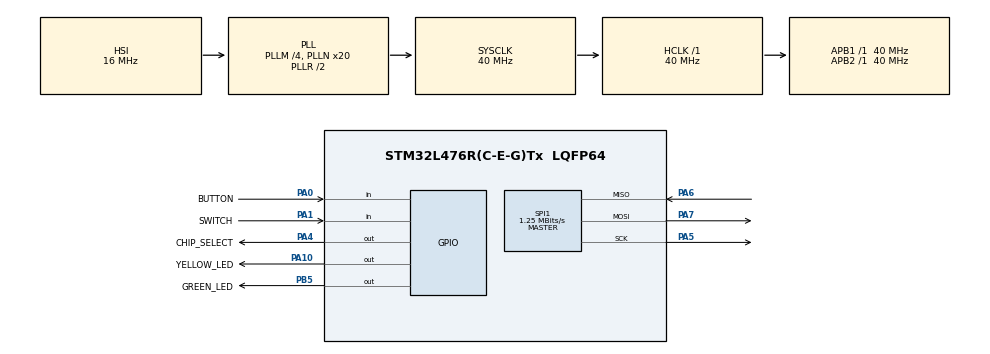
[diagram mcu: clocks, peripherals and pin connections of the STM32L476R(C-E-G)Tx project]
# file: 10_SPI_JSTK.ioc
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Mcu.Family=STM32L4
Mcu.Name=STM32L476R(C-E-G)Tx
Mcu.Package=LQFP64
NVIC.PriorityGroup=NVIC_PRIORITYGROUP_4
PA0.GPIO_Label=BUTTON
PA0.Signal=GPIO_Input
PA1.GPIO_Label=SWITCH
PA1.Signal=GPIO_Input
PA10.GPIO_Label=YELLOW_LED
PA10.Signal=GPIO_Output
PA13\ (JTMS-SWDIO).Mode=Serial_Wire
PA13\ (JTMS-SWDIO).Signal=SYS_JTMS-SWDIO
PA14\ (JTCK-SWCLK).Mode=Serial_Wire
PA14\ (JTCK-SWCLK).Signal=SYS_JTCK-SWCLK
PA4.GPIO_Label=CHIP_SELECT
PA4.Signal=GPIO_Output
PA5.Mode=Full_Duplex_Master
PA5.Signal=SPI1_SCK
PA6.Mode=Full_Duplex_Master
PA6.Signal=SPI1_MISO
PA7.Mode=Full_Duplex_Master
PA7.Signal=SPI1_MOSI
PB5.GPIO_Label=GREEN_LED
PB5.Signal=GPIO_Output
PH0-OSC_IN\ (PH0).Mode=HSE-External-Oscillator
PH0-OSC_IN\ (PH0).Signal=RCC_OSC_IN
PH1-OSC_OUT\ (PH1).Mode=HSE-External-Oscillator
PH1-OSC_OUT\ (PH1).Signal=RCC_OSC_OUT
ProjectManager.HeapSize=0x200
ProjectManager.StackSize=0x400
ProjectManager.TargetToolchain=MDK-ARM V5
RCC.ADCFreq_Value=16000000
RCC.AHBFreq_Value=40000000
RCC.APB1Freq_Value=40000000
RCC.APB1TimFreq_Value=40000000
RCC.APB2Freq_Value=40000000
RCC.APB2TimFreq_Value=40000000
RCC.CortexFreq_Value=40000000
RCC.HCLKFreq_Value=40000000
RCC.HSE_VALUE=8000000
RCC.HSI_VALUE=16000000
RCC.LSE_VALUE=32768
RCC.MSI_VALUE=4000000
RCC.PLLM=4
RCC.PLLN=20
RCC.PLLSourceVirtual=RCC_PLLSOURCE_HSI
RCC.PREFETCH_ENABLE=1
RCC.SYSCLKFreq_VALUE=40000000
RCC.SYSCLKSource=RCC_SYSCLKSOURCE_PLLCLK
RCC.USBFreq_Value=16000000
RCC.VCOOutputFreq_Value=80000000
SPI1.BaudRatePrescaler=SPI_BAUDRATEPRESCALER_32
SPI1.CalculateBaudRate=1.25 MBits/s
SPI1.DataSize=SPI_DATASIZE_8BIT
SPI1.Direction=SPI_DIRECTION_2LINES
SPI1.FirstBit=SPI_FIRSTBIT_MSB
SPI1.Mode=SPI_MODE_MASTER
SPI1.VirtualType=VM_MASTER
board=NUCLEO-L476RG

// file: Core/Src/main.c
/* USER CODE BEGIN Header */
/**
  ******************************************************************************
  * @file           : main.c
  * @brief          : Main program body
  ******************************************************************************
  * @attention
  *
  * Copyright (c) 2023 STMicroelectronics.
  * All rights reserved.
  *
  * This software is licensed under terms that can be found in the LICENSE file
  * in the root directory of this software component.
  * If no LICENSE file comes with this software, it is provided AS-IS.
  *
  ******************************************************************************
  */
/* USER CODE END Header */
#include "main.h"
#include <stdbool.h>

SPI_HandleTypeDef hspi1;

void SystemClock_Config(void);
static void MX_GPIO_Init(void);
static void MX_SPI1_Init(void);

/* USER CODE BEGIN 0 */
uint8_t slaveAddress[5];
uint8_t spiData[5];
uint8_t status = 0;
uint8_t jstk_led[5];
/* USER CODE END 0 */
bool transmit = false;
int main(void)
{

  /* MCU Configuration--------------------------------------------------------*/

  /* Reset of all peripherals, Initializes the Flash interface and the Systick. */
  HAL_Init();

  /* Configure the system clock */
  SystemClock_Config();

  /* Initialize all configured peripherals */
  MX_GPIO_Init();
  MX_SPI1_Init();
  /* USER CODE BEGIN 2 */
	HAL_GPIO_WritePin(CHIP_SELECT_GPIO_Port, CHIP_SELECT_Pin, GPIO_PIN_SET);
	//HAL_Delay(10);
  /* USER CODE END 2 */
	slaveAddress[0] = 0xC0;
	jstk_led[0] = 0x80;
  /* Infinite loop */
  /* USER CODE BEGIN WHILE */
  while (1)
  {
		if(!HAL_GPIO_ReadPin(SWITCH_GPIO_Port,SWITCH_Pin)){
			transmit = !transmit;
			HAL_Delay(200);
		}
    /* USER CODE END WHILE */

		if(transmit){

			HAL_GPIO_WritePin(CHIP_SELECT_GPIO_Port, CHIP_SELECT_Pin, GPIO_PIN_RESET);

			for(uint8_t k=0; k<5; k++){
				HAL_SPI_Transmit(&hspi1, &jstk_led[k], 1, 10);
			}

			HAL_GPIO_WritePin(CHIP_SELECT_GPIO_Port, CHIP_SELECT_Pin, GPIO_PIN_SET);

			if(!HAL_GPIO_ReadPin(BUTTON_GPIO_Port,BUTTON_Pin)){
				status = !status;
				HAL_Delay(200);
			}

			if(status == 0){
				jstk_led[0] = 0x80;
			}else{
				jstk_led[0] = 0x81;
			}
		}
		else{

			HAL_GPIO_WritePin(CHIP_SELECT_GPIO_Port, CHIP_SELECT_Pin, GPIO_PIN_RESET);

			for(uint8_t i=0; i<5; i++){
				HAL_SPI_Transmit(&hspi1, &slaveAddress[i], 1, 10);

			}

			for(uint8_t j=0; j<5; j++){
				HAL_SPI_Receive(&hspi1, &spiData[j], 1, 10);

			}

			HAL_GPIO_WritePin(CHIP_SELECT_GPIO_Port, CHIP_SELECT_Pin, GPIO_PIN_SET);

			if(spiData[0] <= 35){
				HAL_GPIO_WritePin(YELLOW_LED_GPIO_Port,YELLOW_LED_Pin,GPIO_PIN_SET);
				HAL_GPIO_WritePin(GREEN_LED_GPIO_Port,GREEN_LED_Pin,GPIO_PIN_RESET);
			}else if(spiData[0] >= 220){
				HAL_GPIO_WritePin(YELLOW_LED_GPIO_Port,YELLOW_LED_Pin,GPIO_PIN_RESET);
				HAL_GPIO_WritePin(GREEN_LED_GPIO_Port,GREEN_LED_Pin,GPIO_PIN_SET);
			}else{
				HAL_GPIO_WritePin(YELLOW_LED_GPIO_Port,YELLOW_LED_Pin,GPIO_PIN_RESET);
				HAL_GPIO_WritePin(GREEN_LED_GPIO_Port,GREEN_LED_Pin,GPIO_PIN_RESET);
			}
		}
  }
}

void SystemClock_Config(void)
{
  RCC_OscInitTypeDef RCC_OscInitStruct = {0};
  RCC_ClkInitTypeDef RCC_ClkInitStruct = {0};

  /** Configure the main internal regulator output voltage
  */
  if (HAL_PWREx_ControlVoltageScaling(PWR_REGULATOR_VOLTAGE_SCALE1) != HAL_OK)
  {
    Error_Handler();
  }

  /** Initializes the RCC Oscillators according to the specified parameters
  * in the RCC_OscInitTypeDef structure.
  */
  RCC_OscInitStruct.OscillatorType = RCC_OSCILLATORTYPE_HSI;
  RCC_OscInitStruct.HSIState = RCC_HSI_ON;
  RCC_OscInitStruct.HSICalibrationValue = RCC_HSICALIBRATION_DEFAULT;
  RCC_OscInitStruct.PLL.PLLState = RCC_PLL_ON;
  RCC_OscInitStruct.PLL.PLLSource = RCC_PLLSOURCE_HSI;
  RCC_OscInitStruct.PLL.PLLM = 4;
  RCC_OscInitStruct.PLL.PLLN = 20;
  RCC_OscInitStruct.PLL.PLLP = RCC_PLLP_DIV7;
  RCC_OscInitStruct.PLL.PLLQ = RCC_PLLQ_DIV2;
  RCC_OscInitStruct.PLL.PLLR = RCC_PLLR_DIV2;
  if (HAL_RCC_OscConfig(&RCC_OscInitStruct) != HAL_OK)
  {
    Error_Handler();
  }

  /** Initializes the CPU, AHB and APB buses clocks
  */
  RCC_ClkInitStruct.ClockType = RCC_CLOCKTYPE_HCLK|RCC_CLOCKTYPE_SYSCLK
                              |RCC_CLOCKTYPE_PCLK1|RCC_CLOCKTYPE_PCLK2;
  RCC_ClkInitStruct.SYSCLKSource = RCC_SYSCLKSOURCE_PLLCLK;
  RCC_ClkInitStruct.AHBCLKDivider = RCC_SYSCLK_DIV1;
  RCC_ClkInitStruct.APB1CLKDivider = RCC_HCLK_DIV1;
  RCC_ClkInitStruct.APB2CLKDivider = RCC_HCLK_DIV1;

  if (HAL_RCC_ClockConfig(&RCC_ClkInitStruct, FLASH_LATENCY_2) != HAL_OK)
  {
    Error_Handler();
  }
}

static void MX_SPI1_Init(void)
{

  /* SPI1 parameter configuration*/
  hspi1.Instance = SPI1;
  hspi1.Init.Mode = SPI_MODE_MASTER;
  hspi1.Init.Direction = SPI_DIRECTION_2LINES;
  hspi1.Init.DataSize = SPI_DATASIZE_8BIT;
  hspi1.Init.CLKPolarity = SPI_POLARITY_LOW;
  hspi1.Init.CLKPhase = SPI_PHASE_1EDGE;
  hspi1.Init.NSS = SPI_NSS_SOFT;
  hspi1.Init.BaudRatePrescaler = SPI_BAUDRATEPRESCALER_32;
  hspi1.Init.FirstBit = SPI_FIRSTBIT_MSB;
  hspi1.Init.TIMode = SPI_TIMODE_DISABLE;
  hspi1.Init.CRCCalculation = SPI_CRCCALCULATION_DISABLE;
  hspi1.Init.CRCPolynomial = 7;
  hspi1.Init.CRCLength = SPI_CRC_LENGTH_DATASIZE;
  hspi1.Init.NSSPMode = SPI_NSS_PULSE_ENABLE;
  if (HAL_SPI_Init(&hspi1) != HAL_OK)
  {
    Error_Handler();
  }

}

static void MX_GPIO_Init(void)
{
  GPIO_InitTypeDef GPIO_InitStruct = {0};

  /* GPIO Ports Clock Enable */
  __HAL_RCC_GPIOH_CLK_ENABLE();
  __HAL_RCC_GPIOA_CLK_ENABLE();
  __HAL_RCC_GPIOB_CLK_ENABLE();

  /*Configure GPIO pin Output Level */
  HAL_GPIO_WritePin(GPIOA, CHIP_SELECT_Pin|YELLOW_LED_Pin, GPIO_PIN_RESET);

  /*Configure GPIO pin Output Level */
  HAL_GPIO_WritePin(GREEN_LED_GPIO_Port, GREEN_LED_Pin, GPIO_PIN_RESET);

  /*Configure GPIO pins : BUTTON_Pin SWITCH_Pin */
  GPIO_InitStruct.Pin = BUTTON_Pin|SWITCH_Pin;
  GPIO_InitStruct.Mode = GPIO_MODE_INPUT;
  GPIO_InitStruct.Pull = GPIO_NOPULL;
  HAL_GPIO_Init(GPIOA, &GPIO_InitStruct);

  /*Configure GPIO pins : CHIP_SELECT_Pin YELLOW_LED_Pin */
  GPIO_InitStruct.Pin = CHIP_SELECT_Pin|YELLOW_LED_Pin;
  GPIO_InitStruct.Mode = GPIO_MODE_OUTPUT_PP;
  GPIO_InitStruct.Pull = GPIO_NOPULL;
  GPIO_InitStruct.Speed = GPIO_SPEED_FREQ_LOW;
  HAL_GPIO_Init(GPIOA, &GPIO_InitStruct);

  /*Configure GPIO pin : GREEN_LED_Pin */
  GPIO_InitStruct.Pin = GREEN_LED_Pin;
  GPIO_InitStruct.Mode = GPIO_MODE_OUTPUT_PP;
  GPIO_InitStruct.Pull = GPIO_NOPULL;
  GPIO_InitStruct.Speed = GPIO_SPEED_FREQ_LOW;
  HAL_GPIO_Init(GREEN_LED_GPIO_Port, &GPIO_InitStruct);

}

void Error_Handler(void)
{
  __disable_irq();
  while (1)
  {
  }
}
